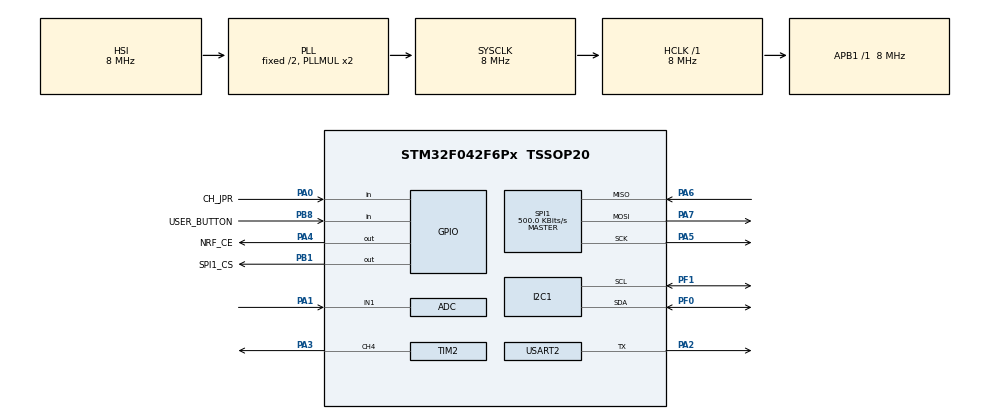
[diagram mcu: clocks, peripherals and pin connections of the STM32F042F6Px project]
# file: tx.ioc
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ADC.ClockPrescaler=ADC_CLOCK_ASYNC_DIV1
ADC.ContinuousConvMode=DISABLE
ADC.DMAContinuousRequests=DISABLE
ADC.DataAlign=ADC_DATAALIGN_RIGHT
ADC.DiscontinuousConvMode=DISABLE
ADC.EOCSelection=ADC_EOC_SINGLE_CONV
ADC.EnableAnalogWatchDog=false
ADC.ExternalTrigConv=ADC_SOFTWARE_START
ADC.ExternalTrigConvEdge=ADC_EXTERNALTRIGCONVEDGE_NONE
ADC.LowPowerAutoPowerOff=DISABLE
ADC.LowPowerAutoWait=DISABLE
ADC.Overrun=ADC_OVR_DATA_PRESERVED
ADC.Resolution=ADC_RESOLUTION_8B
ADC.SamplingTime=ADC_SAMPLETIME_71CYCLES_5
ADC.ScanConvMode=ADC_SCAN_DIRECTION_FORWARD
IWDG.Prescaler=IWDG_PRESCALER_32
Mcu.Family=STM32F0
Mcu.Name=STM32F042F6Px
Mcu.Package=TSSOP20
NVIC.RTC_IRQn=true\:1\:0\:true\:false\:true\:true
NVIC.TIM17_IRQn=true\:0\:0\:false\:false\:true\:true
PA0.GPIO_Label=CH_JPR
PA0.GPIO_PuPd=GPIO_PULLUP
PA0.Signal=GPIO_Input
PA1.Mode=IN1
PA1.Signal=ADC_IN1
PA13.Mode=Serial_Wire
PA13.Signal=SYS_SWDIO
PA14.Mode=Serial_Wire
PA14.Signal=SYS_SWCLK
PA2.Mode=Half_duplex(single_wire_mode)
PA2.Signal=USART2_TX
PA3.Signal=S_TIM2_CH4
PA4.GPIO_Label=NRF_CE
PA4.Signal=GPIO_Output
PA5.Mode=Full_Duplex_Master
PA5.Signal=SPI1_SCK
PA6.Mode=Full_Duplex_Master
PA6.Signal=SPI1_MISO
PA7.Mode=Full_Duplex_Master
PA7.Signal=SPI1_MOSI
PB1.GPIO_Label=SPI1_CS
PB1.PinState=GPIO_PIN_SET
PB1.Signal=GPIO_Output
PB8.GPIO_Label=USER_BUTTON
PB8.GPIO_PuPd=GPIO_NOPULL
PB8.Signal=GPIO_Input
PF0-OSC_IN.Mode=I2C
PF0-OSC_IN.Signal=I2C1_SDA
PF1-OSC_OUT.Mode=I2C
PF1-OSC_OUT.Signal=I2C1_SCL
ProjectManager.HeapSize=0x200
ProjectManager.StackSize=0x400
ProjectManager.TargetToolchain=MDK-ARM V5
RCC.AHBFreq_Value=8000000
RCC.APB1Freq_Value=8000000
RCC.APB1TimFreq_Value=8000000
RCC.HCLKFreq_Value=8000000
RCC.SYSCLKFreq_VALUE=8000000
RTC.Alarm=RTC_ALARM_A
RTC.AlarmMaskDateWeekDay=RTC_ALARMMASK_DATEWEEKDAY
RTC.AlarmMaskHours=RTC_ALARMMASK_HOURS
RTC.AlarmMaskMinutes=RTC_ALARMMASK_MINUTES
RTC.AsynchPrediv=26
RTC.Seconds_A=5
RTC.SynchPrediv=4
SH.S_TIM2_CH4.0=TIM2_CH4,PWM Generation4 CH4
SPI1.BaudRatePrescaler=SPI_BAUDRATEPRESCALER_16
SPI1.CalculateBaudRate=500.0 KBits/s
SPI1.DataSize=SPI_DATASIZE_8BIT
SPI1.Direction=SPI_DIRECTION_2LINES
SPI1.Mode=SPI_MODE_MASTER
SPI1.VirtualType=VM_MASTER
TIM17.Period=16666
TIM17.Prescaler=7
TIM2.Channel-PWM\ Generation4\ CH4=TIM_CHANNEL_4
TIM2.Period=255
TIM2.Prescaler=399
USART2.BaudRate=115200
USART2.Mode=MODE_TX
USART2.TxPinLevelInvertParam=UART_ADVFEATURE_TXINV_DISABLE
USART2.VirtualMode-Half_duplex(single_wire_mode)=VM_ASYNC
VP_IWDG_VS_IWDG.Mode=IWDG_Activate
VP_RTC_VS_RTC_Activate.Mode=RTC_Enabled
VP_RTC_VS_RTC_Alarm_A_Intern.Mode=Alarm A
VP_RTC_VS_RTC_Calendar.Mode=RTC_Calendar
VP_TIM17_VS_ClockSourceINT.Mode=Enable_Timer
VP_TIM2_VS_ClockSourceINT.Mode=Internal
board=custom

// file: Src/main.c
/**
  ******************************************************************************
  * @file           : main.c
  * @brief          : Main program body
  ******************************************************************************
  * This notice applies to any and all portions of this file
  * that are not between comment pairs USER CODE BEGIN and
  * USER CODE END. Other portions of this file, whether
  * inserted by the user or by software development tools
  * are owned by their respective copyright owners.
  *
  * Copyright (c) 2020 STMicroelectronics International N.V.
  * All rights reserved.
  *
  * Redistribution and use in source and binary forms, with or without
  * modification, are permitted, provided that the following conditions are met:
  *
  * 1. Redistribution of source code must retain the above copyright notice,
  *    this list of conditions and the following disclaimer.
  * 2. Redistributions in binary form must reproduce the above copyright notice,
  *    this list of conditions and the following disclaimer in the documentation
  *    and/or other materials provided with the distribution.
  * 3. Neither the name of STMicroelectronics nor the names of other
  *    contributors to this software may be used to endorse or promote products
  *    derived from this software without specific written permission.
  * 4. This software, including modifications and/or derivative works of this
  *    software, must execute solely and exclusively on microcontroller or
  *    microprocessor devices manufactured by or for STMicroelectronics.
  * 5. Redistribution and use of this software other than as permitted under
  *    this license is void and will automatically terminate your rights under
  *    this license.
  *
  * THIS SOFTWARE IS PROVIDED BY STMICROELECTRONICS AND CONTRIBUTORS "AS IS"
  * AND ANY EXPRESS, IMPLIED OR STATUTORY WARRANTIES, INCLUDING, BUT NOT
  * LIMITED TO, THE IMPLIED WARRANTIES OF MERCHANTABILITY, FITNESS FOR A
  * PARTICULAR PURPOSE AND NON-INFRINGEMENT OF THIRD PARTY INTELLECTUAL PROPERTY
  * RIGHTS ARE DISCLAIMED TO THE FULLEST EXTENT PERMITTED BY LAW. IN NO EVENT
  * SHALL STMICROELECTRONICS OR CONTRIBUTORS BE LIABLE FOR ANY DIRECT, INDIRECT,
  * INCIDENTAL, SPECIAL, EXEMPLARY, OR CONSEQUENTIAL DAMAGES (INCLUDING, BUT NOT
  * LIMITED TO, PROCUREMENT OF SUBSTITUTE GOODS OR SERVICES; LOSS OF USE, DATA,
  * OR PROFITS; OR BUSINESS INTERRUPTION) HOWEVER CAUSED AND ON ANY THEORY OF
  * LIABILITY, WHETHER IN CONTRACT, STRICT LIABILITY, OR TORT (INCLUDING
  * NEGLIGENCE OR OTHERWISE) ARISING IN ANY WAY OUT OF THE USE OF THIS SOFTWARE,
  * EVEN IF ADVISED OF THE POSSIBILITY OF SUCH DAMAGE.
  *
  ******************************************************************************
  */
#include "main.h"
#include "stm32f0xx_hal.h"
#include "usb_device.h"

/* USER CODE BEGIN Includes */
#include <stdlib.h>
#include "shared.h"
#include "helpers.h"
#include "nrf24.h"
#include "VL53L0X.h"
#include "animation.h"
#include "ee.h"
#include "my_usb.h"

#define STATE_IDLE 0
#define STATE_TRIGGERED 1

#define CHARGING_VOLTAGE_THRESHOLD_MV 4000

/* USER CODE END Includes */

ADC_HandleTypeDef hadc;

I2C_HandleTypeDef hi2c1;

IWDG_HandleTypeDef hiwdg;

RTC_HandleTypeDef hrtc;

SPI_HandleTypeDef hspi1;

TIM_HandleTypeDef htim2;
TIM_HandleTypeDef htim17;

UART_HandleTypeDef huart2;

/* USER CODE BEGIN PV */
/* Private variables ---------------------------------------------------------*/
uint8_t data_array[NRF_PAYLOAD_SIZE];
uint8_t rx_address[5] = {0xBE,0xAD,0xA5,0xBA,0xBE};
uint8_t tx_address[5] = {0xDA,0xBB,0xED,0xC0,0x0C};

uint16_t baseline, this_reading;
uint8_t new_stat_packet = 1;
uint8_t current_state = STATE_IDLE;
uint16_t vbat_mV;
uint16_t vbat_mV_prev;
uint16_t power_on_time_5s;
uint16_t trigger_upper_threshold, trigger_lower_threshold;
uint8_t this_battery_adc_value;
/* USER CODE END PV */

void SystemClock_Config(void);
static void MX_GPIO_Init(void);
static void MX_USART2_UART_Init(void);
static void MX_I2C1_Init(void);
static void MX_SPI1_Init(void);
static void MX_RTC_Init(void);
static void MX_TIM2_Init(void);
static void MX_TIM17_Init(void);
static void MX_ADC_Init(void);
static void MX_IWDG_Init(void);

void HAL_TIM_MspPostInit(TIM_HandleTypeDef *htim);

/* USER CODE BEGIN PFP */
/* Private function prototypes -----------------------------------------------*/

/* USER CODE END PFP */

/* USER CODE BEGIN 0 */
int fputc(int ch, FILE *f)
{
  my_usb_putchar((uint8_t)ch);
  if(daytripper_config.print_debug_info)
    HAL_UART_Transmit(&huart2, (unsigned char *)&ch, 1, 10);
  return ch;
}

void HAL_TIM_PeriodElapsedCallback(TIM_HandleTypeDef *htim)
{
  if(htim->Instance == TIM17)
    animation_update();
}

void start_measurement(void)
{
  if(vbat_mV > CHARGING_VOLTAGE_THRESHOLD_MV)
    startContinuous(1);
  else
    startContinuous(1000/daytripper_config.refresh_rate_Hz);
  align_timing();
}

uint8_t is_rtc_calibrated;
uint32_t rtc_calib_temp;
uint8_t rct_calibration_value;
int8_t rtc_offset;

void HAL_RTC_AlarmAEventCallback(RTC_HandleTypeDef *hrtc)
{
  if(is_rtc_calibrated)
    return;
  rct_calibration_value = HAL_GetTick() - rtc_calib_temp;
}

const static uint8_t rtc_calib_lookup[32] = {0, 0, 0, 0, 1, 1, 2, 2, 3, 3, 3, 4, 4, 5, 5, 6, 6, 6, 7, 7, 8, 8, 9, 9, 9, 10, 10, 11, 11, 12, 12, 12};

void rtc_calibrate(void)
{
  rtc_calib_temp = HAL_GetTick();
  rtc_test(&hrtc, 200);
  HAL_Delay(300);
  is_rtc_calibrated = 1;
  if(rct_calibration_value < 184)
    rct_calibration_value = 184;
  else if(rct_calibration_value > 215)
    rct_calibration_value = 215;
  rtc_offset = rtc_calib_lookup[rct_calibration_value - 184];
}

uint8_t is_trigger(uint16_t thisss)
{
	// printf("%d (%d %d) (%d %d)\n", thisss, trigger_lower_threshold, trigger_upper_threshold, daytripper_config.range_max_mm, daytripper_config.range_min_mm);
	if(thisss > daytripper_config.range_max_mm || thisss < daytripper_config.range_min_mm)
		return 0;
	return thisss < trigger_lower_threshold || thisss > trigger_upper_threshold;
}

/* USER CODE END 0 */

int main(void)
{

  /* MCU Configuration----------------------------------------------------------*/

  /* Reset of all peripherals, Initializes the Flash interface and the Systick. */
  HAL_Init();

  /* Configure the system clock */
  SystemClock_Config();

  /* Initialize all configured peripherals */
  MX_GPIO_Init();
  MX_USART2_UART_Init();
  MX_I2C1_Init();
  MX_SPI1_Init();
  MX_TIM2_Init();
  MX_TIM17_Init();
  MX_ADC_Init();
  MX_USB_DEVICE_Init();
  /* USER CODE BEGIN 2 */
  my_usb_init();
  MX_RTC_Init();
  HAL_RTC_DeactivateAlarm(&hrtc, RTC_ALARM_A);
  NRF_ON();
  VL53L0X_init();
  dt_conf_load_default(&daytripper_config);
  printf("\n\ndaytripper TX\ndekuNukem 2020\n\n");
  dt_conf_load(&daytripper_config);
  // dt_conf_print(&daytripper_config);
  animation_init(&htim17, &htim2);
  start_animation(ANIMATION_TYPE_BREATHING);
  HAL_Delay(2000);

  if(HAL_RTCEx_BKUPRead(&hrtc, 0) == RTC_BKUP_SLEEP)
  {
    // printf("rtc shutdown\n");
    sys_shutdown();
  }
  for (int i = 0; i < BATTERY_HISTORY_SIZE; ++i)
  {
    add_battery_history(get_battery_adc_reading());
    HAL_Delay(50);
  }
  if(is_low_battery())
    sys_shutdown();

  memset(battery_reading_history, 0, BATTERY_HISTORY_SIZE);
  vbat_mV = get_battery_adc_reading() * ADC_COEFFICIENT;
  vbat_mV_prev = vbat_mV;
  rtc_calibrate();
  // printf("rct_calibration_value: %d\n", rct_calibration_value);
  // printf("rtc_offset: %d\n", rtc_offset);
  // this should be behind get_battery_adc_reading, so it can completely shut down in low battery situation
  MX_IWDG_Init();
  /* USER CODE END 2 */

  /* Infinite loop */
  /* USER CODE BEGIN WHILE */
  setTimeout(500);
  // in microseconds, longer time better accruacy, but consumes more power
  setMeasurementTimingBudget((uint32_t)daytripper_config.tof_timing_budget_ms * 1000); // default 33000

  // printf("initializing NRF...");
  nrf24_init();
  nrf24_config(NRF_CHANNEL, NRF_PAYLOAD_SIZE);
  tx_address[4] = daytripper_config.tx_wireless_channel;
  nrf24_tx_address(tx_address);
  nrf24_rx_address(rx_address);
  HAL_GPIO_WritePin(NRF_CE_GPIO_Port, NRF_CE_Pin, GPIO_PIN_RESET);
  HAL_GPIO_WritePin(SPI1_CS_GPIO_Port, SPI1_CS_Pin, GPIO_PIN_SET);
  // printf(" done\n");
  tof_calibrate(&baseline, &trigger_upper_threshold, &trigger_lower_threshold);
  start_measurement();
  start_animation(ANIMATION_TYPE_CONST_OFF);
  while (1)
  {
    HAL_IWDG_Refresh(&hiwdg);
    parse_cmd(my_usb_readline());

    // every 5 seconds
    if(rtc_counter > 5000)
    {
      power_on_time_5s++; // update power-on counter
      if(power_on_time_5s % 180 == 0) // 5 * 180 = 900s = 15mins, send stat update every 15 minutes
        new_stat_packet = 1;
      this_battery_adc_value = get_battery_adc_reading();
      vbat_mV = this_battery_adc_value * ADC_COEFFICIENT;
      if(power_on_time_5s % 60 == 0)
      {
        add_battery_history(this_battery_adc_value);
        // printf("vbat_mV: %d\n", vbat_mV);
        if(is_low_battery())
        {
          // write to RTC register, kick dog then reset, check rtc register on startup, and go to sleep if needed
          HAL_RTCEx_BKUPWrite(&hrtc, 0, RTC_BKUP_SLEEP);
          // printf("HHHH\n");
          HAL_IWDG_Refresh(&hiwdg);
          NVIC_SystemReset();
        }
      }

      rtc_counter = 0;
    }

  /* USER CODE END WHILE */

  /* USER CODE BEGIN 3 */
    if(new_stat_packet)
    {
      build_packet_stat(data_array, vbat_mV, power_on_time_5s);
      // printf("sending stat... vbat_mV: %d\n", vbat_mV);
      send_packet(data_array);
      new_stat_packet = 0;
    }

    // get a new distance reading from laser ToF sensor
    this_reading = get_continuous_distance_reading(&is_reading_valid);
    if(is_reading_valid == 0)
      goto sleep;

    // if the change in distance is big enough...
    if(current_state == STATE_IDLE && is_trigger(this_reading))
    {
      uint8_t count = 0;
      uint16_t temp;
      printf(">> b:%d t0:%d ", baseline, this_reading);
      // .. take another reading back-to-back, to make sure it's not sensor noise
      while(count < daytripper_config.nr_sensitivity)
      {
        HAL_IWDG_Refresh(&hiwdg);
        temp = get_single_distance_reading(&is_reading_valid);
        printf("t%d:%d ", count+1, temp);
        if(is_reading_valid == 0)
          continue;
        if(is_trigger(temp) == 0)
        {
          printf("X\n");
          start_measurement();
          goto sleep;
        }
        count++;
      }
      printf("\n");
      build_packet_trig(data_array, baseline, this_reading);
      send_packet(data_array);
      if(daytripper_config.use_led)
        start_animation(ANIMATION_TYPE_CONST_ON);
      start_measurement();
      current_state = STATE_TRIGGERED;
    }
    else if(current_state == STATE_TRIGGERED && is_trigger(this_reading) == 0)
    {
      start_animation(ANIMATION_TYPE_CONST_OFF);
      current_state = STATE_IDLE;
      align_timing();
    }

    sleep:
    HAL_IWDG_Refresh(&hiwdg);
    nrf24_powerDown();

    if(vbat_mV > CHARGING_VOLTAGE_THRESHOLD_MV && vbat_mV_prev <= CHARGING_VOLTAGE_THRESHOLD_MV)
    {
      printf("charging\n");
      start_measurement();
    }
    if(vbat_mV <= CHARGING_VOLTAGE_THRESHOLD_MV && vbat_mV_prev > CHARGING_VOLTAGE_THRESHOLD_MV)
    {
      printf("unplugged\n");
      start_measurement();
    }
    vbat_mV_prev = vbat_mV;

    if(vbat_mV < CHARGING_VOLTAGE_THRESHOLD_MV) // only sleep while on battery, when charging go full speed
      rtc_sleep(&hrtc, 1000/daytripper_config.refresh_rate_Hz - rtc_offset);
    else
      run_time_update(24); // if charging, dont sleep, but still update the time count
  }
  /* USER CODE END 3 */

}

void SystemClock_Config(void)
{

  RCC_OscInitTypeDef RCC_OscInitStruct;
  RCC_ClkInitTypeDef RCC_ClkInitStruct;
  RCC_PeriphCLKInitTypeDef PeriphClkInit;

    /**Initializes the CPU, AHB and APB busses clocks
    */
  RCC_OscInitStruct.OscillatorType = RCC_OSCILLATORTYPE_HSI|RCC_OSCILLATORTYPE_HSI14
                              |RCC_OSCILLATORTYPE_HSI48|RCC_OSCILLATORTYPE_LSI;
  RCC_OscInitStruct.HSIState = RCC_HSI_ON;
  RCC_OscInitStruct.HSI48State = RCC_HSI48_ON;
  RCC_OscInitStruct.HSI14State = RCC_HSI14_ON;
  RCC_OscInitStruct.HSICalibrationValue = 16;
  RCC_OscInitStruct.HSI14CalibrationValue = 16;
  RCC_OscInitStruct.LSIState = RCC_LSI_ON;
  RCC_OscInitStruct.PLL.PLLState = RCC_PLL_ON;
  RCC_OscInitStruct.PLL.PLLSource = RCC_PLLSOURCE_HSI;
  RCC_OscInitStruct.PLL.PLLMUL = RCC_PLL_MUL2;
  RCC_OscInitStruct.PLL.PREDIV = RCC_PREDIV_DIV1;
  if (HAL_RCC_OscConfig(&RCC_OscInitStruct) != HAL_OK)
  {
    _Error_Handler(__FILE__, __LINE__);
  }

    /**Initializes the CPU, AHB and APB busses clocks
    */
  RCC_ClkInitStruct.ClockType = RCC_CLOCKTYPE_HCLK|RCC_CLOCKTYPE_SYSCLK
                              |RCC_CLOCKTYPE_PCLK1;
  RCC_ClkInitStruct.SYSCLKSource = RCC_SYSCLKSOURCE_PLLCLK;
  RCC_ClkInitStruct.AHBCLKDivider = RCC_SYSCLK_DIV1;
  RCC_ClkInitStruct.APB1CLKDivider = RCC_HCLK_DIV1;

  if (HAL_RCC_ClockConfig(&RCC_ClkInitStruct, FLASH_LATENCY_0) != HAL_OK)
  {
    _Error_Handler(__FILE__, __LINE__);
  }

  PeriphClkInit.PeriphClockSelection = RCC_PERIPHCLK_USB|RCC_PERIPHCLK_I2C1
                              |RCC_PERIPHCLK_RTC;
  PeriphClkInit.I2c1ClockSelection = RCC_I2C1CLKSOURCE_SYSCLK;
  PeriphClkInit.RTCClockSelection = RCC_RTCCLKSOURCE_LSI;
  PeriphClkInit.UsbClockSelection = RCC_USBCLKSOURCE_HSI48;

  if (HAL_RCCEx_PeriphCLKConfig(&PeriphClkInit) != HAL_OK)
  {
    _Error_Handler(__FILE__, __LINE__);
  }

    /**Configure the Systick interrupt time
    */
  HAL_SYSTICK_Config(HAL_RCC_GetHCLKFreq()/1000);

    /**Configure the Systick
    */
  HAL_SYSTICK_CLKSourceConfig(SYSTICK_CLKSOURCE_HCLK);

  /* SysTick_IRQn interrupt configuration */
  HAL_NVIC_SetPriority(SysTick_IRQn, 0, 0);
}

/* ADC init function */
static void MX_ADC_Init(void)
{

  ADC_ChannelConfTypeDef sConfig;

    /**Configure the global features of the ADC (Clock, Resolution, Data Alignment and number of conversion)
    */
  hadc.Instance = ADC1;
  hadc.Init.ClockPrescaler = ADC_CLOCK_ASYNC_DIV1;
  hadc.Init.Resolution = ADC_RESOLUTION_8B;
  hadc.Init.DataAlign = ADC_DATAALIGN_RIGHT;
  hadc.Init.ScanConvMode = ADC_SCAN_DIRECTION_FORWARD;
  hadc.Init.EOCSelection = ADC_EOC_SINGLE_CONV;
  hadc.Init.LowPowerAutoWait = DISABLE;
  hadc.Init.LowPowerAutoPowerOff = DISABLE;
  hadc.Init.ContinuousConvMode = DISABLE;
  hadc.Init.DiscontinuousConvMode = DISABLE;
  hadc.Init.ExternalTrigConv = ADC_SOFTWARE_START;
  hadc.Init.ExternalTrigConvEdge = ADC_EXTERNALTRIGCONVEDGE_NONE;
  hadc.Init.DMAContinuousRequests = DISABLE;
  hadc.Init.Overrun = ADC_OVR_DATA_PRESERVED;
  if (HAL_ADC_Init(&hadc) != HAL_OK)
  {
    _Error_Handler(__FILE__, __LINE__);
  }

    /**Configure for the selected ADC regular channel to be converted.
    */
  sConfig.Channel = ADC_CHANNEL_1;
  sConfig.Rank = ADC_RANK_CHANNEL_NUMBER;
  sConfig.SamplingTime = ADC_SAMPLETIME_71CYCLES_5;
  if (HAL_ADC_ConfigChannel(&hadc, &sConfig) != HAL_OK)
  {
    _Error_Handler(__FILE__, __LINE__);
  }

}

/* I2C1 init function */
static void MX_I2C1_Init(void)
{

  hi2c1.Instance = I2C1;
  hi2c1.Init.Timing = 0x00303D5B;
  hi2c1.Init.OwnAddress1 = 0;
  hi2c1.Init.AddressingMode = I2C_ADDRESSINGMODE_7BIT;
  hi2c1.Init.DualAddressMode = I2C_DUALADDRESS_DISABLE;
  hi2c1.Init.OwnAddress2 = 0;
  hi2c1.Init.OwnAddress2Masks = I2C_OA2_NOMASK;
  hi2c1.Init.GeneralCallMode = I2C_GENERALCALL_DISABLE;
  hi2c1.Init.NoStretchMode = I2C_NOSTRETCH_DISABLE;
  if (HAL_I2C_Init(&hi2c1) != HAL_OK)
  {
    _Error_Handler(__FILE__, __LINE__);
  }

    /**Configure Analogue filter
    */
  if (HAL_I2CEx_ConfigAnalogFilter(&hi2c1, I2C_ANALOGFILTER_ENABLE) != HAL_OK)
  {
    _Error_Handler(__FILE__, __LINE__);
  }

    /**Configure Digital filter
    */
  if (HAL_I2CEx_ConfigDigitalFilter(&hi2c1, 0) != HAL_OK)
  {
    _Error_Handler(__FILE__, __LINE__);
  }

}

/* IWDG init function */
static void MX_IWDG_Init(void)
{

  hiwdg.Instance = IWDG;
  hiwdg.Init.Prescaler = IWDG_PRESCALER_32;
  hiwdg.Init.Window = 4095;
  hiwdg.Init.Reload = 4095;
  if (HAL_IWDG_Init(&hiwdg) != HAL_OK)
  {
    _Error_Handler(__FILE__, __LINE__);
  }

}

/* RTC init function */
static void MX_RTC_Init(void)
{

  RTC_TimeTypeDef sTime;
  RTC_DateTypeDef sDate;
  RTC_AlarmTypeDef sAlarm;

    /**Initialize RTC Only
    */
  hrtc.Instance = RTC;
  hrtc.Init.HourFormat = RTC_HOURFORMAT_24;
  hrtc.Init.AsynchPrediv = 18;
  hrtc.Init.SynchPrediv = 0;
  hrtc.Init.OutPut = RTC_OUTPUT_DISABLE;
  hrtc.Init.OutPutPolarity = RTC_OUTPUT_POLARITY_HIGH;
  hrtc.Init.OutPutType = RTC_OUTPUT_TYPE_OPENDRAIN;
  if (HAL_RTC_Init(&hrtc) != HAL_OK)
  {
    _Error_Handler(__FILE__, __LINE__);
  }

    /**Initialize RTC and set the Time and Date
    */
  sTime.Hours = 0;
  sTime.Minutes = 0;
  sTime.Seconds = 0;
  sTime.DayLightSaving = RTC_DAYLIGHTSAVING_NONE;
  sTime.StoreOperation = RTC_STOREOPERATION_RESET;
  if (HAL_RTC_SetTime(&hrtc, &sTime, RTC_FORMAT_BIN) != HAL_OK)
  {
    _Error_Handler(__FILE__, __LINE__);
  }

  sDate.WeekDay = RTC_WEEKDAY_MONDAY;
  sDate.Month = RTC_MONTH_JANUARY;
  sDate.Date = 1;
  sDate.Year = 0;

  if (HAL_RTC_SetDate(&hrtc, &sDate, RTC_FORMAT_BIN) != HAL_OK)
  {
    _Error_Handler(__FILE__, __LINE__);
  }

    /**Enable the Alarm A
    */
  sAlarm.AlarmTime.Hours = 0;
  sAlarm.AlarmTime.Minutes = 0;
  sAlarm.AlarmTime.Seconds = 5;
  sAlarm.AlarmTime.SubSeconds = 0;
  sAlarm.AlarmTime.DayLightSaving = RTC_DAYLIGHTSAVING_NONE;
  sAlarm.AlarmTime.StoreOperation = RTC_STOREOPERATION_RESET;
  sAlarm.AlarmMask = RTC_ALARMMASK_DATEWEEKDAY;
  sAlarm.AlarmSubSecondMask = RTC_ALARMSUBSECONDMASK_ALL;
  sAlarm.AlarmDateWeekDaySel = RTC_ALARMDATEWEEKDAYSEL_DATE;
  sAlarm.AlarmDateWeekDay = 1;
  sAlarm.Alarm = RTC_ALARM_A;
  if (HAL_RTC_SetAlarm_IT(&hrtc, &sAlarm, RTC_FORMAT_BIN) != HAL_OK)
  {
    _Error_Handler(__FILE__, __LINE__);
  }

}

/* SPI1 init function */
static void MX_SPI1_Init(void)
{

  /* SPI1 parameter configuration*/
  hspi1.Instance = SPI1;
  hspi1.Init.Mode = SPI_MODE_MASTER;
  hspi1.Init.Direction = SPI_DIRECTION_2LINES;
  hspi1.Init.DataSize = SPI_DATASIZE_8BIT;
  hspi1.Init.CLKPolarity = SPI_POLARITY_LOW;
  hspi1.Init.CLKPhase = SPI_PHASE_1EDGE;
  hspi1.Init.NSS = SPI_NSS_SOFT;
  hspi1.Init.BaudRatePrescaler = SPI_BAUDRATEPRESCALER_4;
  hspi1.Init.FirstBit = SPI_FIRSTBIT_MSB;
  hspi1.Init.TIMode = SPI_TIMODE_DISABLE;
  hspi1.Init.CRCCalculation = SPI_CRCCALCULATION_DISABLE;
  hspi1.Init.CRCPolynomial = 7;
  hspi1.Init.CRCLength = SPI_CRC_LENGTH_DATASIZE;
  hspi1.Init.NSSPMode = SPI_NSS_PULSE_ENABLE;
  if (HAL_SPI_Init(&hspi1) != HAL_OK)
  {
    _Error_Handler(__FILE__, __LINE__);
  }

}

/* TIM2 init function */
static void MX_TIM2_Init(void)
{

  TIM_ClockConfigTypeDef sClockSourceConfig;
  TIM_MasterConfigTypeDef sMasterConfig;
  TIM_OC_InitTypeDef sConfigOC;

  htim2.Instance = TIM2;
  htim2.Init.Prescaler = 799;
  htim2.Init.CounterMode = TIM_COUNTERMODE_UP;
  htim2.Init.Period = 255;
  htim2.Init.ClockDivision = TIM_CLOCKDIVISION_DIV1;
  htim2.Init.AutoReloadPreload = TIM_AUTORELOAD_PRELOAD_DISABLE;
  if (HAL_TIM_Base_Init(&htim2) != HAL_OK)
  {
    _Error_Handler(__FILE__, __LINE__);
  }

  sClockSourceConfig.ClockSource = TIM_CLOCKSOURCE_INTERNAL;
  if (HAL_TIM_ConfigClockSource(&htim2, &sClockSourceConfig) != HAL_OK)
  {
    _Error_Handler(__FILE__, __LINE__);
  }

  if (HAL_TIM_PWM_Init(&htim2) != HAL_OK)
  {
    _Error_Handler(__FILE__, __LINE__);
  }

  sMasterConfig.MasterOutputTrigger = TIM_TRGO_RESET;
  sMasterConfig.MasterSlaveMode = TIM_MASTERSLAVEMODE_DISABLE;
  if (HAL_TIMEx_MasterConfigSynchronization(&htim2, &sMasterConfig) != HAL_OK)
  {
    _Error_Handler(__FILE__, __LINE__);
  }

  sConfigOC.OCMode = TIM_OCMODE_PWM1;
  sConfigOC.Pulse = 0;
  sConfigOC.OCPolarity = TIM_OCPOLARITY_HIGH;
  sConfigOC.OCFastMode = TIM_OCFAST_DISABLE;
  if (HAL_TIM_PWM_ConfigChannel(&htim2, &sConfigOC, TIM_CHANNEL_4) != HAL_OK)
  {
    _Error_Handler(__FILE__, __LINE__);
  }

  HAL_TIM_MspPostInit(&htim2);

}

/* TIM17 init function */
static void MX_TIM17_Init(void)
{

  htim17.Instance = TIM17;
  htim17.Init.Prescaler = 15;
  htim17.Init.CounterMode = TIM_COUNTERMODE_UP;
  htim17.Init.Period = 16666;
  htim17.Init.ClockDivision = TIM_CLOCKDIVISION_DIV1;
  htim17.Init.RepetitionCounter = 0;
  htim17.Init.AutoReloadPreload = TIM_AUTORELOAD_PRELOAD_DISABLE;
  if (HAL_TIM_Base_Init(&htim17) != HAL_OK)
  {
    _Error_Handler(__FILE__, __LINE__);
  }

}

/* USART2 init function */
static void MX_USART2_UART_Init(void)
{

  huart2.Instance = USART2;
  huart2.Init.BaudRate = 115200;
  huart2.Init.WordLength = UART_WORDLENGTH_8B;
  huart2.Init.StopBits = UART_STOPBITS_1;
  huart2.Init.Parity = UART_PARITY_NONE;
  huart2.Init.Mode = UART_MODE_TX;
  huart2.Init.HwFlowCtl = UART_HWCONTROL_NONE;
  huart2.Init.OverSampling = UART_OVERSAMPLING_16;
  huart2.Init.OneBitSampling = UART_ONE_BIT_SAMPLE_DISABLE;
  huart2.AdvancedInit.AdvFeatureInit = UART_ADVFEATURE_RXOVERRUNDISABLE_INIT|UART_ADVFEATURE_DMADISABLEONERROR_INIT;
  huart2.AdvancedInit.OverrunDisable = UART_ADVFEATURE_OVERRUN_DISABLE;
  huart2.AdvancedInit.DMADisableonRxError = UART_ADVFEATURE_DMA_DISABLEONRXERROR;
  if (HAL_HalfDuplex_Init(&huart2) != HAL_OK)
  {
    _Error_Handler(__FILE__, __LINE__);
  }

}

/** Configure pins as
        * Analog
        * Input
        * Output
        * EVENT_OUT
        * EXTI
*/
static void MX_GPIO_Init(void)
{

  GPIO_InitTypeDef GPIO_InitStruct;

  /* GPIO Ports Clock Enable */
  __HAL_RCC_GPIOB_CLK_ENABLE();
  __HAL_RCC_GPIOF_CLK_ENABLE();
  __HAL_RCC_GPIOA_CLK_ENABLE();

  /*Configure GPIO pin Output Level */
  HAL_GPIO_WritePin(NRF_VCC_GPIO_Port, NRF_VCC_Pin, GPIO_PIN_SET);

  /*Configure GPIO pin Output Level */
  HAL_GPIO_WritePin(NRF_CE_GPIO_Port, NRF_CE_Pin, GPIO_PIN_RESET);

  /*Configure GPIO pin Output Level */
  HAL_GPIO_WritePin(SPI1_CS_GPIO_Port, SPI1_CS_Pin, GPIO_PIN_SET);

  /*Configure GPIO pin : USER_BUTTON_Pin */
  GPIO_InitStruct.Pin = USER_BUTTON_Pin;
  GPIO_InitStruct.Mode = GPIO_MODE_INPUT;
  GPIO_InitStruct.Pull = GPIO_NOPULL;
  HAL_GPIO_Init(USER_BUTTON_GPIO_Port, &GPIO_InitStruct);

  /*Configure GPIO pin : NRF_VCC_Pin */
  GPIO_InitStruct.Pin = NRF_VCC_Pin;
  GPIO_InitStruct.Mode = GPIO_MODE_OUTPUT_OD;
  GPIO_InitStruct.Pull = GPIO_NOPULL;
  GPIO_InitStruct.Speed = GPIO_SPEED_FREQ_LOW;
  HAL_GPIO_Init(NRF_VCC_GPIO_Port, &GPIO_InitStruct);

  /*Configure GPIO pin : NRF_CE_Pin */
  GPIO_InitStruct.Pin = NRF_CE_Pin;
  GPIO_InitStruct.Mode = GPIO_MODE_OUTPUT_PP;
  GPIO_InitStruct.Pull = GPIO_NOPULL;
  GPIO_InitStruct.Speed = GPIO_SPEED_FREQ_LOW;
  HAL_GPIO_Init(NRF_CE_GPIO_Port, &GPIO_InitStruct);

  /*Configure GPIO pin : SPI1_CS_Pin */
  GPIO_InitStruct.Pin = SPI1_CS_Pin;
  GPIO_InitStruct.Mode = GPIO_MODE_OUTPUT_PP;
  GPIO_InitStruct.Pull = GPIO_NOPULL;
  GPIO_InitStruct.Speed = GPIO_SPEED_FREQ_LOW;
  HAL_GPIO_Init(SPI1_CS_GPIO_Port, &GPIO_InitStruct);

}

void _Error_Handler(char *file, int line)
{
  while(1)
  {
  }
}

/************************ (C) COPYRIGHT STMicroelectronics *****END OF FILE****/
